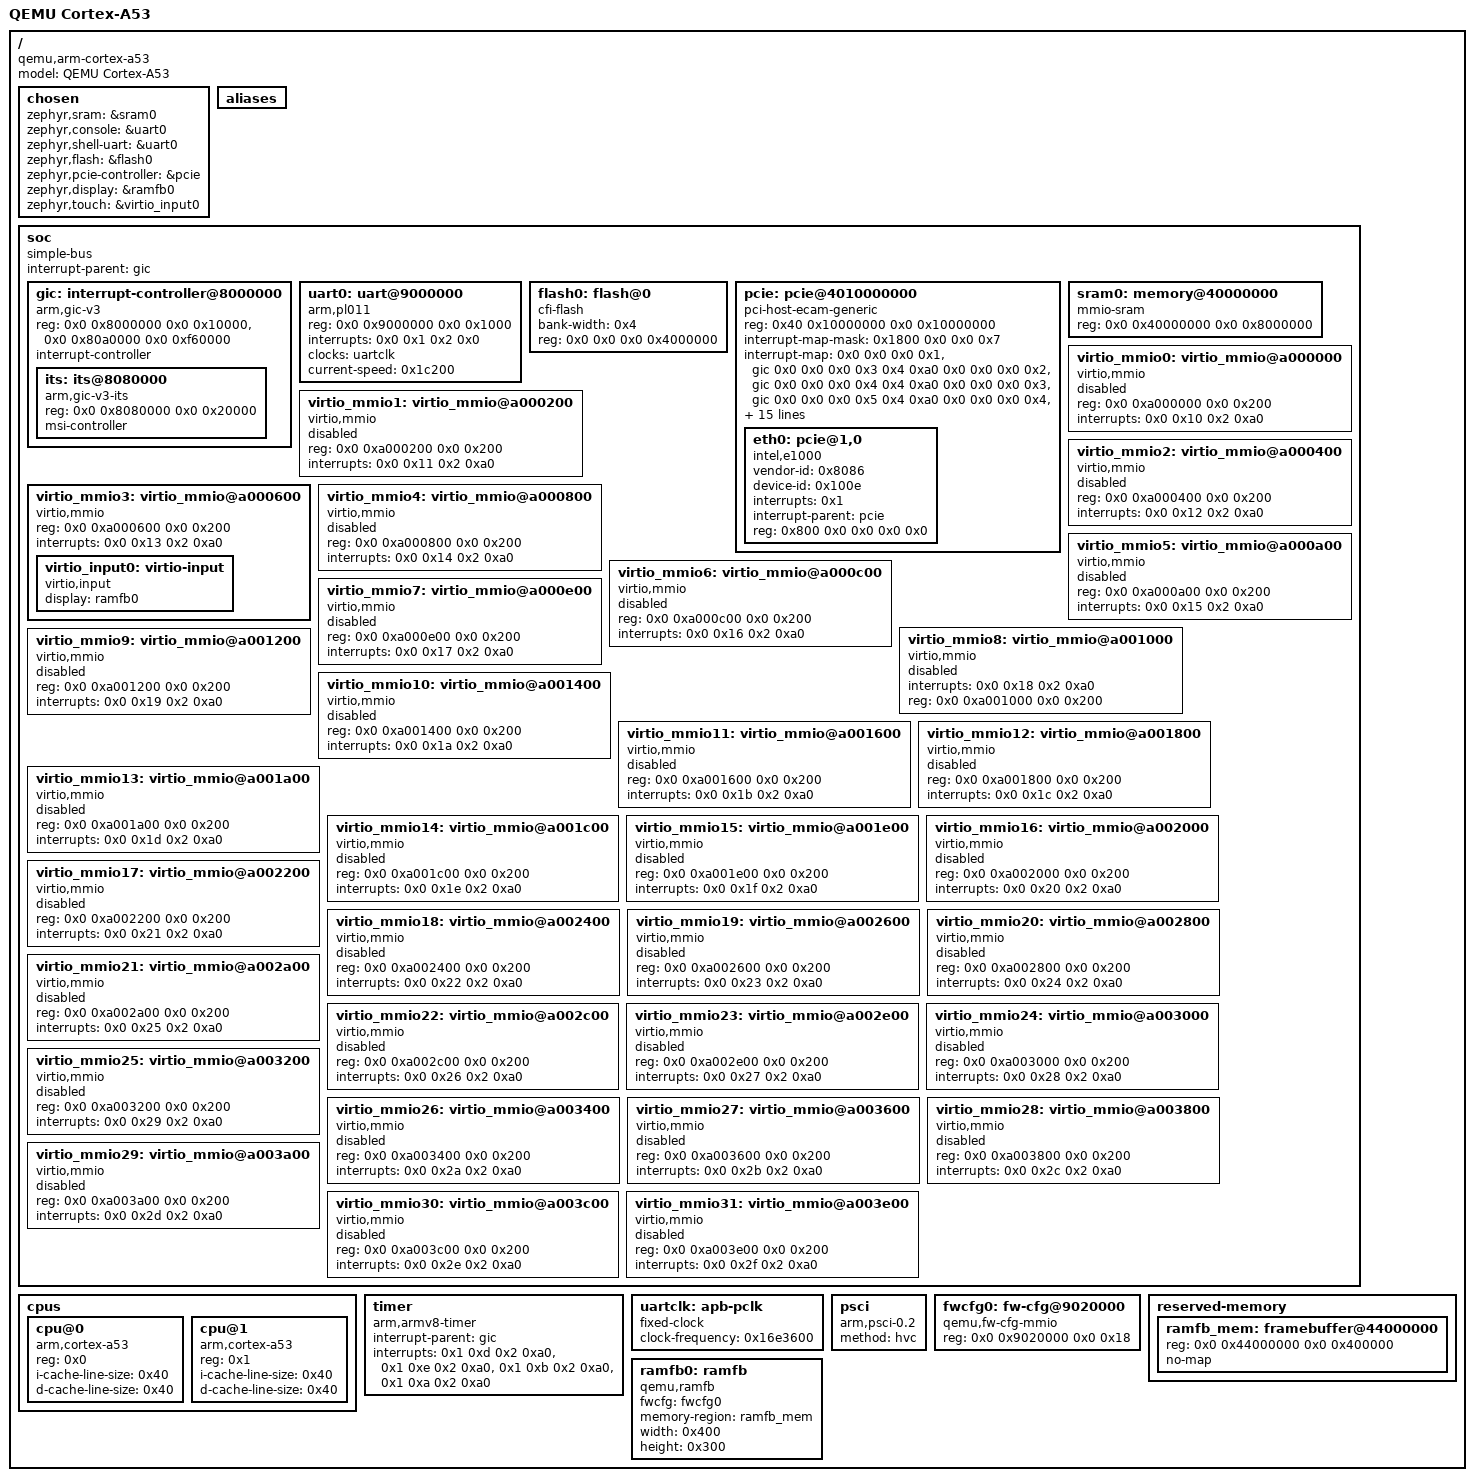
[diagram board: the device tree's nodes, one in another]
/dts-v1/;

/* node '/' defined in zephyr/dts/common/skeleton.dtsi:9 */
/ {
	#address-cells = < 0x2 >;           /* in zephyr/dts/arm64/qemu/qemu-virt-a53.dtsi:22 */
	#size-cells = < 0x2 >;              /* in zephyr/dts/arm64/qemu/qemu-virt-a53.dtsi:23 */
	model = "QEMU Cortex-A53";          /* in zephyr/boards/qemu/cortex_a53/qemu_cortex_a53.dts:12 */
	compatible = "qemu,arm-cortex-a53"; /* in zephyr/boards/qemu/cortex_a53/qemu_cortex_a53.dts:13 */

	/* node '/chosen' defined in zephyr/dts/common/skeleton.dtsi:13 */
	chosen {
		zephyr,sram = &sram0;           /* in zephyr/boards/qemu/cortex_a53/qemu_cortex_a53.dts:21 */
		zephyr,console = &uart0;        /* in zephyr/boards/qemu/cortex_a53/qemu_cortex_a53.dts:22 */
		zephyr,shell-uart = &uart0;     /* in zephyr/boards/qemu/cortex_a53/qemu_cortex_a53.dts:23 */
		zephyr,flash = &flash0;         /* in zephyr/boards/qemu/cortex_a53/qemu_cortex_a53.dts:24 */
		zephyr,pcie-controller = &pcie; /* in zephyr/boards/qemu/cortex_a53/qemu_cortex_a53.dts:25 */
		zephyr,display = &ramfb0;       /* in zephyr/boards/qemu/cortex_a53/qemu_cortex_a53.dts:26 */
		zephyr,touch = &virtio_input0;  /* in zephyr/boards/qemu/cortex_a53/qemu_cortex_a53.dts:27 */
	};

	/* node '/aliases' defined in zephyr/dts/common/skeleton.dtsi:15 */
	aliases {
	};

	/* node '/soc' defined in zephyr/dts/arm64/armv8-a.dtsi:10 */
	soc {
		compatible = "simple-bus";   /* in zephyr/dts/arm64/armv8-a.dtsi:13 */
		#address-cells = < 0x2 >;    /* in zephyr/dts/arm64/qemu/qemu-virt-a53.dtsi:66 */
		#size-cells = < 0x2 >;       /* in zephyr/dts/arm64/qemu/qemu-virt-a53.dtsi:67 */
		ranges;                      /* in zephyr/dts/arm64/qemu/qemu-virt-a53.dtsi:68 */
		interrupt-parent = < &gic >; /* in zephyr/dts/arm64/qemu/qemu-virt-a53.dtsi:70 */

		/* node '/soc/interrupt-controller@8000000' defined in zephyr/dts/arm64/qemu/qemu-virt-a53.dtsi:72 */
		gic: interrupt-controller@8000000 {
			compatible = "arm,gic-v3",
			             "arm,gic";               /* in zephyr/dts/arm64/qemu/qemu-virt-a53.dtsi:73 */
			reg = < 0x0 0x8000000 0x0 0x10000 >,
			      < 0x0 0x80a0000 0x0 0xf60000 >; /* in zephyr/dts/arm64/qemu/qemu-virt-a53.dtsi:74 */
			interrupt-controller;                 /* in zephyr/dts/arm64/qemu/qemu-virt-a53.dtsi:76 */
			#interrupt-cells = < 0x4 >;           /* in zephyr/dts/arm64/qemu/qemu-virt-a53.dtsi:77 */
			status = "okay";                      /* in zephyr/dts/arm64/qemu/qemu-virt-a53.dtsi:78 */
			#size-cells = < 0x2 >;                /* in zephyr/dts/arm64/qemu/qemu-virt-a53.dtsi:79 */
			#address-cells = < 0x2 >;             /* in zephyr/dts/arm64/qemu/qemu-virt-a53.dtsi:80 */
			phandle = < 0x1 >;                    /* in zephyr/dts/arm64/qemu/qemu-virt-a53.dtsi:70 */

			/* node '/soc/interrupt-controller@8000000/its@8080000' defined in zephyr/dts/arm64/qemu/qemu-virt-a53.dtsi:82 */
			its: its@8080000 {
				compatible = "arm,gic-v3-its";       /* in zephyr/dts/arm64/qemu/qemu-virt-a53.dtsi:83 */
				reg = < 0x0 0x8080000 0x0 0x20000 >; /* in zephyr/dts/arm64/qemu/qemu-virt-a53.dtsi:84 */
				msi-controller;                      /* in zephyr/dts/arm64/qemu/qemu-virt-a53.dtsi:85 */
				phandle = < 0x3 >;                   /* in zephyr/dts/arm64/qemu/qemu-virt-a53.dtsi:151 */
			};
		};

		/* node '/soc/uart@9000000' defined in zephyr/dts/arm64/qemu/qemu-virt-a53.dtsi:89 */
		uart0: uart@9000000 {
			compatible = "arm,pl011";           /* in zephyr/dts/arm64/qemu/qemu-virt-a53.dtsi:90 */
			reg = < 0x0 0x9000000 0x0 0x1000 >; /* in zephyr/dts/arm64/qemu/qemu-virt-a53.dtsi:91 */
			interrupts = < 0x0 0x1 0x2 0x0 >;   /* in zephyr/dts/arm64/qemu/qemu-virt-a53.dtsi:93 */
			interrupt-names = "irq_0";          /* in zephyr/dts/arm64/qemu/qemu-virt-a53.dtsi:94 */
			clocks = < &uartclk >;              /* in zephyr/dts/arm64/qemu/qemu-virt-a53.dtsi:95 */
			status = "okay";                    /* in zephyr/boards/qemu/cortex_a53/qemu_cortex_a53.dts:289 */
			current-speed = < 0x1c200 >;        /* in zephyr/boards/qemu/cortex_a53/qemu_cortex_a53.dts:290 */
		};

		/* node '/soc/flash@0' defined in zephyr/dts/arm64/qemu/qemu-virt-a53.dtsi:98 */
		flash0: flash@0 {
			compatible = "cfi-flash";        /* in zephyr/dts/arm64/qemu/qemu-virt-a53.dtsi:99 */
			bank-width = < 0x4 >;            /* in zephyr/dts/arm64/qemu/qemu-virt-a53.dtsi:100 */
			reg = < 0x0 0x0 0x0 0x4000000 >; /* in zephyr/dts/arm64/qemu/qemu-virt-a53.dtsi:105 */
		};

		/* node '/soc/pcie@4010000000' defined in zephyr/dts/arm64/qemu/qemu-virt-a53.dtsi:108 */
		pcie: pcie@4010000000 {
			compatible = "pci-host-ecam-generic";                                                                 /* in zephyr/dts/arm64/qemu/qemu-virt-a53.dtsi:109 */
			device_type = "pci";                                                                                  /* in zephyr/dts/arm64/qemu/qemu-virt-a53.dtsi:110 */
			reg = < 0x40 0x10000000 0x0 0x10000000 >;                                                             /* in zephyr/dts/arm64/qemu/qemu-virt-a53.dtsi:111 */
			#size-cells = < 0x2 >;                                                                                /* in zephyr/dts/arm64/qemu/qemu-virt-a53.dtsi:112 */
			#address-cells = < 0x3 >;                                                                             /* in zephyr/dts/arm64/qemu/qemu-virt-a53.dtsi:113 */
			ranges = < 0x1000000 0x0 0x0 0x0 0x3eff0000 0x0 0x10000 0x2000000 0x0 0x10000000 0x0 0x10000000
			           0x0 0x2eff0000 0x3000000 0x80 0x0 0x80 0x0 0x80 0x0 >;                                     /* in zephyr/dts/arm64/qemu/qemu-virt-a53.dtsi:114 */
			#interrupt-cells = < 0x1 >;                                                                           /* in zephyr/dts/arm64/qemu/qemu-virt-a53.dtsi:117 */
			interrupt-map-mask = < 0x1800 0x0 0x0 0x7 >;                                                          /* in zephyr/dts/arm64/qemu/qemu-virt-a53.dtsi:118 */
			interrupt-map = < 0x0 0x0 0x0 0x1 &gic 0x0 0x0 0x0 0x3 0x4 0xa0 0x0 0x0 0x0 0x2 &gic 0x0 0x0 0x0 0x4
			                  0x4 0xa0 0x0 0x0 0x0 0x3 &gic 0x0 0x0 0x0 0x5 0x4 0xa0 0x0 0x0 0x0 0x4 &gic 0x0 0x0
			                  0x0 0x6 0x4 0xa0 0x800 0x0 0x0 0x1 &gic 0x0 0x0 0x0 0x4 0x4 0xa0 0x800 0x0 0x0 0x2
			                  &gic 0x0 0x0 0x0 0x5 0x4 0xa0 0x800 0x0 0x0 0x3 &gic 0x0 0x0 0x0 0x6 0x4 0xa0 0x800
			                  0x0 0x0 0x4 &gic 0x0 0x0 0x0 0x3 0x4 0xa0 0x1000 0x0 0x0 0x1 &gic 0x0 0x0 0x0 0x5
			                  0x4 0xa0 0x1000 0x0 0x0 0x2 &gic 0x0 0x0 0x0 0x6 0x4 0xa0 0x1000 0x0 0x0 0x3 &gic
			                  0x0 0x0 0x0 0x3 0x4 0xa0 0x1000 0x0 0x0 0x4 &gic 0x0 0x0 0x0 0x4 0x4 0xa0 0x1800
			                  0x0 0x0 0x1 &gic 0x0 0x0 0x0 0x6 0x4 0xa0 0x1800 0x0 0x0 0x2 &gic 0x0 0x0 0x0 0x3
			                  0x4 0xa0 0x1800 0x0 0x0 0x3 &gic 0x0 0x0 0x0 0x4 0x4 0xa0 0x1800 0x0 0x0 0x4 &gic
			                  0x0 0x0 0x0 0x5 0x4 0xa0 >;                                                         /* in zephyr/dts/arm64/qemu/qemu-virt-a53.dtsi:119 */
			msi-parent = < &its >;                                                                                /* in zephyr/dts/arm64/qemu/qemu-virt-a53.dtsi:151 */
			bus-range = < 0x0 0xff >;                                                                             /* in zephyr/dts/arm64/qemu/qemu-virt-a53.dtsi:152 */
			phandle = < 0x4 >;                                                                                    /* in zephyr/boards/qemu/cortex_a53/qemu_cortex_a53.dts:309 */

			/* node '/soc/pcie@4010000000/pcie@1,0' defined in zephyr/boards/qemu/cortex_a53/qemu_cortex_a53.dts:304 */
			eth0: pcie@1,0 {
				compatible = "intel,e1000";      /* in zephyr/boards/qemu/cortex_a53/qemu_cortex_a53.dts:305 */
				vendor-id = < 0x8086 >;          /* in zephyr/boards/qemu/cortex_a53/qemu_cortex_a53.dts:306 */
				device-id = < 0x100e >;          /* in zephyr/boards/qemu/cortex_a53/qemu_cortex_a53.dts:307 */
				interrupts = < 0x1 >;            /* in zephyr/boards/qemu/cortex_a53/qemu_cortex_a53.dts:308 */
				interrupt-parent = < &pcie >;    /* in zephyr/boards/qemu/cortex_a53/qemu_cortex_a53.dts:309 */
				reg = < 0x800 0x0 0x0 0x0 0x0 >; /* in zephyr/boards/qemu/cortex_a53/qemu_cortex_a53.dts:310 */
				status = "okay";                 /* in zephyr/boards/qemu/cortex_a53/qemu_cortex_a53.dts:311 */
			};
		};

		/* node '/soc/memory@40000000' defined in zephyr/boards/qemu/cortex_a53/qemu_cortex_a53.dts:31 */
		sram0: memory@40000000 {
			compatible = "mmio-sram";               /* in zephyr/boards/qemu/cortex_a53/qemu_cortex_a53.dts:32 */
			reg = < 0x0 0x40000000 0x0 0x8000000 >; /* in zephyr/boards/qemu/cortex_a53/qemu_cortex_a53.dts:33 */
		};

		/* node '/soc/virtio_mmio@a000000' defined in zephyr/boards/qemu/cortex_a53/qemu_cortex_a53.dts:36 */
		virtio_mmio0: virtio_mmio@a000000 {
			compatible = "virtio,mmio";         /* in zephyr/boards/qemu/cortex_a53/qemu_cortex_a53.dts:37 */
			reg = < 0x0 0xa000000 0x0 0x200 >;  /* in zephyr/boards/qemu/cortex_a53/qemu_cortex_a53.dts:38 */
			interrupts = < 0x0 0x10 0x2 0xa0 >; /* in zephyr/boards/qemu/cortex_a53/qemu_cortex_a53.dts:39 */
			status = "disabled";                /* in zephyr/boards/qemu/cortex_a53/qemu_cortex_a53.dts:40 */
		};

		/* node '/soc/virtio_mmio@a000200' defined in zephyr/boards/qemu/cortex_a53/qemu_cortex_a53.dts:43 */
		virtio_mmio1: virtio_mmio@a000200 {
			compatible = "virtio,mmio";         /* in zephyr/boards/qemu/cortex_a53/qemu_cortex_a53.dts:44 */
			reg = < 0x0 0xa000200 0x0 0x200 >;  /* in zephyr/boards/qemu/cortex_a53/qemu_cortex_a53.dts:45 */
			interrupts = < 0x0 0x11 0x2 0xa0 >; /* in zephyr/boards/qemu/cortex_a53/qemu_cortex_a53.dts:46 */
			status = "disabled";                /* in zephyr/boards/qemu/cortex_a53/qemu_cortex_a53.dts:47 */
		};

		/* node '/soc/virtio_mmio@a000400' defined in zephyr/boards/qemu/cortex_a53/qemu_cortex_a53.dts:50 */
		virtio_mmio2: virtio_mmio@a000400 {
			compatible = "virtio,mmio";         /* in zephyr/boards/qemu/cortex_a53/qemu_cortex_a53.dts:51 */
			reg = < 0x0 0xa000400 0x0 0x200 >;  /* in zephyr/boards/qemu/cortex_a53/qemu_cortex_a53.dts:52 */
			interrupts = < 0x0 0x12 0x2 0xa0 >; /* in zephyr/boards/qemu/cortex_a53/qemu_cortex_a53.dts:53 */
			status = "disabled";                /* in zephyr/boards/qemu/cortex_a53/qemu_cortex_a53.dts:54 */
		};

		/* node '/soc/virtio_mmio@a000600' defined in zephyr/boards/qemu/cortex_a53/qemu_cortex_a53.dts:57 */
		virtio_mmio3: virtio_mmio@a000600 {
			compatible = "virtio,mmio";         /* in zephyr/boards/qemu/cortex_a53/qemu_cortex_a53.dts:58 */
			reg = < 0x0 0xa000600 0x0 0x200 >;  /* in zephyr/boards/qemu/cortex_a53/qemu_cortex_a53.dts:59 */
			interrupts = < 0x0 0x13 0x2 0xa0 >; /* in zephyr/boards/qemu/cortex_a53/qemu_cortex_a53.dts:60 */
			status = "okay";                    /* in zephyr/boards/qemu/cortex_a53/qemu_cortex_a53.dts:294 */

			/* node '/soc/virtio_mmio@a000600/virtio-input' defined in zephyr/boards/qemu/cortex_a53/qemu_cortex_a53.dts:296 */
			virtio_input0: virtio-input {
				compatible = "virtio,input"; /* in zephyr/boards/qemu/cortex_a53/qemu_cortex_a53.dts:297 */
				display = < &ramfb0 >;       /* in zephyr/boards/qemu/cortex_a53/qemu_cortex_a53.dts:298 */
				status = "okay";             /* in zephyr/boards/qemu/cortex_a53/qemu_cortex_a53.dts:299 */
			};
		};

		/* node '/soc/virtio_mmio@a000800' defined in zephyr/boards/qemu/cortex_a53/qemu_cortex_a53.dts:64 */
		virtio_mmio4: virtio_mmio@a000800 {
			compatible = "virtio,mmio";         /* in zephyr/boards/qemu/cortex_a53/qemu_cortex_a53.dts:65 */
			reg = < 0x0 0xa000800 0x0 0x200 >;  /* in zephyr/boards/qemu/cortex_a53/qemu_cortex_a53.dts:66 */
			interrupts = < 0x0 0x14 0x2 0xa0 >; /* in zephyr/boards/qemu/cortex_a53/qemu_cortex_a53.dts:67 */
			status = "disabled";                /* in zephyr/boards/qemu/cortex_a53/qemu_cortex_a53.dts:68 */
		};

		/* node '/soc/virtio_mmio@a000a00' defined in zephyr/boards/qemu/cortex_a53/qemu_cortex_a53.dts:71 */
		virtio_mmio5: virtio_mmio@a000a00 {
			compatible = "virtio,mmio";         /* in zephyr/boards/qemu/cortex_a53/qemu_cortex_a53.dts:72 */
			reg = < 0x0 0xa000a00 0x0 0x200 >;  /* in zephyr/boards/qemu/cortex_a53/qemu_cortex_a53.dts:73 */
			interrupts = < 0x0 0x15 0x2 0xa0 >; /* in zephyr/boards/qemu/cortex_a53/qemu_cortex_a53.dts:74 */
			status = "disabled";                /* in zephyr/boards/qemu/cortex_a53/qemu_cortex_a53.dts:75 */
		};

		/* node '/soc/virtio_mmio@a000c00' defined in zephyr/boards/qemu/cortex_a53/qemu_cortex_a53.dts:78 */
		virtio_mmio6: virtio_mmio@a000c00 {
			compatible = "virtio,mmio";         /* in zephyr/boards/qemu/cortex_a53/qemu_cortex_a53.dts:79 */
			reg = < 0x0 0xa000c00 0x0 0x200 >;  /* in zephyr/boards/qemu/cortex_a53/qemu_cortex_a53.dts:80 */
			interrupts = < 0x0 0x16 0x2 0xa0 >; /* in zephyr/boards/qemu/cortex_a53/qemu_cortex_a53.dts:81 */
			status = "disabled";                /* in zephyr/boards/qemu/cortex_a53/qemu_cortex_a53.dts:82 */
		};

		/* node '/soc/virtio_mmio@a000e00' defined in zephyr/boards/qemu/cortex_a53/qemu_cortex_a53.dts:85 */
		virtio_mmio7: virtio_mmio@a000e00 {
			compatible = "virtio,mmio";         /* in zephyr/boards/qemu/cortex_a53/qemu_cortex_a53.dts:86 */
			reg = < 0x0 0xa000e00 0x0 0x200 >;  /* in zephyr/boards/qemu/cortex_a53/qemu_cortex_a53.dts:87 */
			interrupts = < 0x0 0x17 0x2 0xa0 >; /* in zephyr/boards/qemu/cortex_a53/qemu_cortex_a53.dts:88 */
			status = "disabled";                /* in zephyr/boards/qemu/cortex_a53/qemu_cortex_a53.dts:89 */
		};

		/* node '/soc/virtio_mmio@a001000' defined in zephyr/boards/qemu/cortex_a53/qemu_cortex_a53.dts:92 */
		virtio_mmio8: virtio_mmio@a001000 {
			compatible = "virtio,mmio";         /* in zephyr/boards/qemu/cortex_a53/qemu_cortex_a53.dts:93 */
			interrupts = < 0x0 0x18 0x2 0xa0 >; /* in zephyr/boards/qemu/cortex_a53/qemu_cortex_a53.dts:94 */
			reg = < 0x0 0xa001000 0x0 0x200 >;  /* in zephyr/boards/qemu/cortex_a53/qemu_cortex_a53.dts:95 */
			status = "disabled";                /* in zephyr/boards/qemu/cortex_a53/qemu_cortex_a53.dts:96 */
		};

		/* node '/soc/virtio_mmio@a001200' defined in zephyr/boards/qemu/cortex_a53/qemu_cortex_a53.dts:99 */
		virtio_mmio9: virtio_mmio@a001200 {
			compatible = "virtio,mmio";         /* in zephyr/boards/qemu/cortex_a53/qemu_cortex_a53.dts:100 */
			reg = < 0x0 0xa001200 0x0 0x200 >;  /* in zephyr/boards/qemu/cortex_a53/qemu_cortex_a53.dts:101 */
			interrupts = < 0x0 0x19 0x2 0xa0 >; /* in zephyr/boards/qemu/cortex_a53/qemu_cortex_a53.dts:102 */
			status = "disabled";                /* in zephyr/boards/qemu/cortex_a53/qemu_cortex_a53.dts:103 */
		};

		/* node '/soc/virtio_mmio@a001400' defined in zephyr/boards/qemu/cortex_a53/qemu_cortex_a53.dts:106 */
		virtio_mmio10: virtio_mmio@a001400 {
			compatible = "virtio,mmio";         /* in zephyr/boards/qemu/cortex_a53/qemu_cortex_a53.dts:107 */
			reg = < 0x0 0xa001400 0x0 0x200 >;  /* in zephyr/boards/qemu/cortex_a53/qemu_cortex_a53.dts:108 */
			interrupts = < 0x0 0x1a 0x2 0xa0 >; /* in zephyr/boards/qemu/cortex_a53/qemu_cortex_a53.dts:109 */
			status = "disabled";                /* in zephyr/boards/qemu/cortex_a53/qemu_cortex_a53.dts:110 */
		};

		/* node '/soc/virtio_mmio@a001600' defined in zephyr/boards/qemu/cortex_a53/qemu_cortex_a53.dts:113 */
		virtio_mmio11: virtio_mmio@a001600 {
			compatible = "virtio,mmio";         /* in zephyr/boards/qemu/cortex_a53/qemu_cortex_a53.dts:114 */
			reg = < 0x0 0xa001600 0x0 0x200 >;  /* in zephyr/boards/qemu/cortex_a53/qemu_cortex_a53.dts:115 */
			interrupts = < 0x0 0x1b 0x2 0xa0 >; /* in zephyr/boards/qemu/cortex_a53/qemu_cortex_a53.dts:116 */
			status = "disabled";                /* in zephyr/boards/qemu/cortex_a53/qemu_cortex_a53.dts:117 */
		};

		/* node '/soc/virtio_mmio@a001800' defined in zephyr/boards/qemu/cortex_a53/qemu_cortex_a53.dts:120 */
		virtio_mmio12: virtio_mmio@a001800 {
			compatible = "virtio,mmio";         /* in zephyr/boards/qemu/cortex_a53/qemu_cortex_a53.dts:121 */
			reg = < 0x0 0xa001800 0x0 0x200 >;  /* in zephyr/boards/qemu/cortex_a53/qemu_cortex_a53.dts:122 */
			interrupts = < 0x0 0x1c 0x2 0xa0 >; /* in zephyr/boards/qemu/cortex_a53/qemu_cortex_a53.dts:123 */
			status = "disabled";                /* in zephyr/boards/qemu/cortex_a53/qemu_cortex_a53.dts:124 */
		};

		/* node '/soc/virtio_mmio@a001a00' defined in zephyr/boards/qemu/cortex_a53/qemu_cortex_a53.dts:127 */
		virtio_mmio13: virtio_mmio@a001a00 {
			compatible = "virtio,mmio";         /* in zephyr/boards/qemu/cortex_a53/qemu_cortex_a53.dts:128 */
			reg = < 0x0 0xa001a00 0x0 0x200 >;  /* in zephyr/boards/qemu/cortex_a53/qemu_cortex_a53.dts:129 */
			interrupts = < 0x0 0x1d 0x2 0xa0 >; /* in zephyr/boards/qemu/cortex_a53/qemu_cortex_a53.dts:130 */
			status = "disabled";                /* in zephyr/boards/qemu/cortex_a53/qemu_cortex_a53.dts:131 */
		};

		/* node '/soc/virtio_mmio@a001c00' defined in zephyr/boards/qemu/cortex_a53/qemu_cortex_a53.dts:134 */
		virtio_mmio14: virtio_mmio@a001c00 {
			compatible = "virtio,mmio";         /* in zephyr/boards/qemu/cortex_a53/qemu_cortex_a53.dts:135 */
			reg = < 0x0 0xa001c00 0x0 0x200 >;  /* in zephyr/boards/qemu/cortex_a53/qemu_cortex_a53.dts:136 */
			interrupts = < 0x0 0x1e 0x2 0xa0 >; /* in zephyr/boards/qemu/cortex_a53/qemu_cortex_a53.dts:137 */
			status = "disabled";                /* in zephyr/boards/qemu/cortex_a53/qemu_cortex_a53.dts:138 */
		};

		/* node '/soc/virtio_mmio@a001e00' defined in zephyr/boards/qemu/cortex_a53/qemu_cortex_a53.dts:141 */
		virtio_mmio15: virtio_mmio@a001e00 {
			compatible = "virtio,mmio";         /* in zephyr/boards/qemu/cortex_a53/qemu_cortex_a53.dts:142 */
			reg = < 0x0 0xa001e00 0x0 0x200 >;  /* in zephyr/boards/qemu/cortex_a53/qemu_cortex_a53.dts:143 */
			interrupts = < 0x0 0x1f 0x2 0xa0 >; /* in zephyr/boards/qemu/cortex_a53/qemu_cortex_a53.dts:144 */
			status = "disabled";                /* in zephyr/boards/qemu/cortex_a53/qemu_cortex_a53.dts:145 */
		};

		/* node '/soc/virtio_mmio@a002000' defined in zephyr/boards/qemu/cortex_a53/qemu_cortex_a53.dts:148 */
		virtio_mmio16: virtio_mmio@a002000 {
			compatible = "virtio,mmio";         /* in zephyr/boards/qemu/cortex_a53/qemu_cortex_a53.dts:149 */
			reg = < 0x0 0xa002000 0x0 0x200 >;  /* in zephyr/boards/qemu/cortex_a53/qemu_cortex_a53.dts:150 */
			interrupts = < 0x0 0x20 0x2 0xa0 >; /* in zephyr/boards/qemu/cortex_a53/qemu_cortex_a53.dts:151 */
			status = "disabled";                /* in zephyr/boards/qemu/cortex_a53/qemu_cortex_a53.dts:152 */
		};

		/* node '/soc/virtio_mmio@a002200' defined in zephyr/boards/qemu/cortex_a53/qemu_cortex_a53.dts:155 */
		virtio_mmio17: virtio_mmio@a002200 {
			compatible = "virtio,mmio";         /* in zephyr/boards/qemu/cortex_a53/qemu_cortex_a53.dts:156 */
			reg = < 0x0 0xa002200 0x0 0x200 >;  /* in zephyr/boards/qemu/cortex_a53/qemu_cortex_a53.dts:157 */
			interrupts = < 0x0 0x21 0x2 0xa0 >; /* in zephyr/boards/qemu/cortex_a53/qemu_cortex_a53.dts:158 */
			status = "disabled";                /* in zephyr/boards/qemu/cortex_a53/qemu_cortex_a53.dts:159 */
		};

		/* node '/soc/virtio_mmio@a002400' defined in zephyr/boards/qemu/cortex_a53/qemu_cortex_a53.dts:162 */
		virtio_mmio18: virtio_mmio@a002400 {
			compatible = "virtio,mmio";         /* in zephyr/boards/qemu/cortex_a53/qemu_cortex_a53.dts:163 */
			reg = < 0x0 0xa002400 0x0 0x200 >;  /* in zephyr/boards/qemu/cortex_a53/qemu_cortex_a53.dts:164 */
			interrupts = < 0x0 0x22 0x2 0xa0 >; /* in zephyr/boards/qemu/cortex_a53/qemu_cortex_a53.dts:165 */
			status = "disabled";                /* in zephyr/boards/qemu/cortex_a53/qemu_cortex_a53.dts:166 */
		};

		/* node '/soc/virtio_mmio@a002600' defined in zephyr/boards/qemu/cortex_a53/qemu_cortex_a53.dts:169 */
		virtio_mmio19: virtio_mmio@a002600 {
			compatible = "virtio,mmio";         /* in zephyr/boards/qemu/cortex_a53/qemu_cortex_a53.dts:170 */
			reg = < 0x0 0xa002600 0x0 0x200 >;  /* in zephyr/boards/qemu/cortex_a53/qemu_cortex_a53.dts:171 */
			interrupts = < 0x0 0x23 0x2 0xa0 >; /* in zephyr/boards/qemu/cortex_a53/qemu_cortex_a53.dts:172 */
			status = "disabled";                /* in zephyr/boards/qemu/cortex_a53/qemu_cortex_a53.dts:173 */
		};

		/* node '/soc/virtio_mmio@a002800' defined in zephyr/boards/qemu/cortex_a53/qemu_cortex_a53.dts:176 */
		virtio_mmio20: virtio_mmio@a002800 {
			compatible = "virtio,mmio";         /* in zephyr/boards/qemu/cortex_a53/qemu_cortex_a53.dts:177 */
			reg = < 0x0 0xa002800 0x0 0x200 >;  /* in zephyr/boards/qemu/cortex_a53/qemu_cortex_a53.dts:178 */
			interrupts = < 0x0 0x24 0x2 0xa0 >; /* in zephyr/boards/qemu/cortex_a53/qemu_cortex_a53.dts:179 */
			status = "disabled";                /* in zephyr/boards/qemu/cortex_a53/qemu_cortex_a53.dts:180 */
		};

		/* node '/soc/virtio_mmio@a002a00' defined in zephyr/boards/qemu/cortex_a53/qemu_cortex_a53.dts:183 */
		virtio_mmio21: virtio_mmio@a002a00 {
			compatible = "virtio,mmio";         /* in zephyr/boards/qemu/cortex_a53/qemu_cortex_a53.dts:184 */
			reg = < 0x0 0xa002a00 0x0 0x200 >;  /* in zephyr/boards/qemu/cortex_a53/qemu_cortex_a53.dts:185 */
			interrupts = < 0x0 0x25 0x2 0xa0 >; /* in zephyr/boards/qemu/cortex_a53/qemu_cortex_a53.dts:186 */
			status = "disabled";                /* in zephyr/boards/qemu/cortex_a53/qemu_cortex_a53.dts:187 */
		};

		/* node '/soc/virtio_mmio@a002c00' defined in zephyr/boards/qemu/cortex_a53/qemu_cortex_a53.dts:190 */
		virtio_mmio22: virtio_mmio@a002c00 {
			compatible = "virtio,mmio";         /* in zephyr/boards/qemu/cortex_a53/qemu_cortex_a53.dts:191 */
			reg = < 0x0 0xa002c00 0x0 0x200 >;  /* in zephyr/boards/qemu/cortex_a53/qemu_cortex_a53.dts:192 */
			interrupts = < 0x0 0x26 0x2 0xa0 >; /* in zephyr/boards/qemu/cortex_a53/qemu_cortex_a53.dts:193 */
			status = "disabled";                /* in zephyr/boards/qemu/cortex_a53/qemu_cortex_a53.dts:194 */
		};

		/* node '/soc/virtio_mmio@a002e00' defined in zephyr/boards/qemu/cortex_a53/qemu_cortex_a53.dts:197 */
		virtio_mmio23: virtio_mmio@a002e00 {
			compatible = "virtio,mmio";         /* in zephyr/boards/qemu/cortex_a53/qemu_cortex_a53.dts:198 */
			reg = < 0x0 0xa002e00 0x0 0x200 >;  /* in zephyr/boards/qemu/cortex_a53/qemu_cortex_a53.dts:199 */
			interrupts = < 0x0 0x27 0x2 0xa0 >; /* in zephyr/boards/qemu/cortex_a53/qemu_cortex_a53.dts:200 */
			status = "disabled";                /* in zephyr/boards/qemu/cortex_a53/qemu_cortex_a53.dts:201 */
		};

		/* node '/soc/virtio_mmio@a003000' defined in zephyr/boards/qemu/cortex_a53/qemu_cortex_a53.dts:204 */
		virtio_mmio24: virtio_mmio@a003000 {
			compatible = "virtio,mmio";         /* in zephyr/boards/qemu/cortex_a53/qemu_cortex_a53.dts:205 */
			reg = < 0x0 0xa003000 0x0 0x200 >;  /* in zephyr/boards/qemu/cortex_a53/qemu_cortex_a53.dts:206 */
			interrupts = < 0x0 0x28 0x2 0xa0 >; /* in zephyr/boards/qemu/cortex_a53/qemu_cortex_a53.dts:207 */
			status = "disabled";                /* in zephyr/boards/qemu/cortex_a53/qemu_cortex_a53.dts:208 */
		};

		/* node '/soc/virtio_mmio@a003200' defined in zephyr/boards/qemu/cortex_a53/qemu_cortex_a53.dts:211 */
		virtio_mmio25: virtio_mmio@a003200 {
			compatible = "virtio,mmio";         /* in zephyr/boards/qemu/cortex_a53/qemu_cortex_a53.dts:212 */
			reg = < 0x0 0xa003200 0x0 0x200 >;  /* in zephyr/boards/qemu/cortex_a53/qemu_cortex_a53.dts:213 */
			interrupts = < 0x0 0x29 0x2 0xa0 >; /* in zephyr/boards/qemu/cortex_a53/qemu_cortex_a53.dts:214 */
			status = "disabled";                /* in zephyr/boards/qemu/cortex_a53/qemu_cortex_a53.dts:215 */
		};

		/* node '/soc/virtio_mmio@a003400' defined in zephyr/boards/qemu/cortex_a53/qemu_cortex_a53.dts:218 */
		virtio_mmio26: virtio_mmio@a003400 {
			compatible = "virtio,mmio";         /* in zephyr/boards/qemu/cortex_a53/qemu_cortex_a53.dts:219 */
			reg = < 0x0 0xa003400 0x0 0x200 >;  /* in zephyr/boards/qemu/cortex_a53/qemu_cortex_a53.dts:220 */
			interrupts = < 0x0 0x2a 0x2 0xa0 >; /* in zephyr/boards/qemu/cortex_a53/qemu_cortex_a53.dts:221 */
			status = "disabled";                /* in zephyr/boards/qemu/cortex_a53/qemu_cortex_a53.dts:222 */
		};

		/* node '/soc/virtio_mmio@a003600' defined in zephyr/boards/qemu/cortex_a53/qemu_cortex_a53.dts:225 */
		virtio_mmio27: virtio_mmio@a003600 {
			compatible = "virtio,mmio";         /* in zephyr/boards/qemu/cortex_a53/qemu_cortex_a53.dts:226 */
			reg = < 0x0 0xa003600 0x0 0x200 >;  /* in zephyr/boards/qemu/cortex_a53/qemu_cortex_a53.dts:227 */
			interrupts = < 0x0 0x2b 0x2 0xa0 >; /* in zephyr/boards/qemu/cortex_a53/qemu_cortex_a53.dts:228 */
			status = "disabled";                /* in zephyr/boards/qemu/cortex_a53/qemu_cortex_a53.dts:229 */
		};

		/* node '/soc/virtio_mmio@a003800' defined in zephyr/boards/qemu/cortex_a53/qemu_cortex_a53.dts:232 */
		virtio_mmio28: virtio_mmio@a003800 {
			compatible = "virtio,mmio";         /* in zephyr/boards/qemu/cortex_a53/qemu_cortex_a53.dts:233 */
			reg = < 0x0 0xa003800 0x0 0x200 >;  /* in zephyr/boards/qemu/cortex_a53/qemu_cortex_a53.dts:234 */
			interrupts = < 0x0 0x2c 0x2 0xa0 >; /* in zephyr/boards/qemu/cortex_a53/qemu_cortex_a53.dts:235 */
			status = "disabled";                /* in zephyr/boards/qemu/cortex_a53/qemu_cortex_a53.dts:236 */
		};

		/* node '/soc/virtio_mmio@a003a00' defined in zephyr/boards/qemu/cortex_a53/qemu_cortex_a53.dts:239 */
		virtio_mmio29: virtio_mmio@a003a00 {
			compatible = "virtio,mmio";         /* in zephyr/boards/qemu/cortex_a53/qemu_cortex_a53.dts:240 */
			reg = < 0x0 0xa003a00 0x0 0x200 >;  /* in zephyr/boards/qemu/cortex_a53/qemu_cortex_a53.dts:241 */
			interrupts = < 0x0 0x2d 0x2 0xa0 >; /* in zephyr/boards/qemu/cortex_a53/qemu_cortex_a53.dts:242 */
			status = "disabled";                /* in zephyr/boards/qemu/cortex_a53/qemu_cortex_a53.dts:243 */
		};

		/* node '/soc/virtio_mmio@a003c00' defined in zephyr/boards/qemu/cortex_a53/qemu_cortex_a53.dts:246 */
		virtio_mmio30: virtio_mmio@a003c00 {
			compatible = "virtio,mmio";         /* in zephyr/boards/qemu/cortex_a53/qemu_cortex_a53.dts:247 */
			reg = < 0x0 0xa003c00 0x0 0x200 >;  /* in zephyr/boards/qemu/cortex_a53/qemu_cortex_a53.dts:248 */
			interrupts = < 0x0 0x2e 0x2 0xa0 >; /* in zephyr/boards/qemu/cortex_a53/qemu_cortex_a53.dts:249 */
			status = "disabled";                /* in zephyr/boards/qemu/cortex_a53/qemu_cortex_a53.dts:250 */
		};

		/* node '/soc/virtio_mmio@a003e00' defined in zephyr/boards/qemu/cortex_a53/qemu_cortex_a53.dts:253 */
		virtio_mmio31: virtio_mmio@a003e00 {
			compatible = "virtio,mmio";         /* in zephyr/boards/qemu/cortex_a53/qemu_cortex_a53.dts:254 */
			reg = < 0x0 0xa003e00 0x0 0x200 >;  /* in zephyr/boards/qemu/cortex_a53/qemu_cortex_a53.dts:255 */
			interrupts = < 0x0 0x2f 0x2 0xa0 >; /* in zephyr/boards/qemu/cortex_a53/qemu_cortex_a53.dts:256 */
			status = "disabled";                /* in zephyr/boards/qemu/cortex_a53/qemu_cortex_a53.dts:257 */
		};
	};

	/* node '/cpus' defined in zephyr/dts/arm64/qemu/qemu-virt-a53.dtsi:25 */
	cpus {
		#address-cells = < 0x1 >; /* in zephyr/dts/arm64/qemu/qemu-virt-a53.dtsi:26 */
		#size-cells = < 0x0 >;    /* in zephyr/dts/arm64/qemu/qemu-virt-a53.dtsi:27 */

		/* node '/cpus/cpu@0' defined in zephyr/dts/arm64/qemu/qemu-virt-a53.dtsi:29 */
		cpu@0 {
			device_type = "cpu";           /* in zephyr/dts/arm64/qemu/qemu-virt-a53.dtsi:30 */
			compatible = "arm,cortex-a53"; /* in zephyr/dts/arm64/qemu/qemu-virt-a53.dtsi:31 */
			reg = < 0x0 >;                 /* in zephyr/dts/arm64/qemu/qemu-virt-a53.dtsi:32 */
			i-cache-line-size = < 0x40 >;  /* in zephyr/dts/arm64/qemu/qemu-virt-a53.dtsi:33 */
			d-cache-line-size = < 0x40 >;  /* in zephyr/dts/arm64/qemu/qemu-virt-a53.dtsi:34 */
		};

		/* node '/cpus/cpu@1' defined in zephyr/dts/arm64/qemu/qemu-virt-a53.dtsi:37 */
		cpu@1 {
			device_type = "cpu";           /* in zephyr/dts/arm64/qemu/qemu-virt-a53.dtsi:38 */
			compatible = "arm,cortex-a53"; /* in zephyr/dts/arm64/qemu/qemu-virt-a53.dtsi:39 */
			reg = < 0x1 >;                 /* in zephyr/dts/arm64/qemu/qemu-virt-a53.dtsi:40 */
			i-cache-line-size = < 0x40 >;  /* in zephyr/dts/arm64/qemu/qemu-virt-a53.dtsi:41 */
			d-cache-line-size = < 0x40 >;  /* in zephyr/dts/arm64/qemu/qemu-virt-a53.dtsi:42 */
		};
	};

	/* node '/timer' defined in zephyr/dts/arm64/qemu/qemu-virt-a53.dtsi:46 */
	timer {
		compatible = "arm,armv8-timer";    /* in zephyr/dts/arm64/qemu/qemu-virt-a53.dtsi:47 */
		interrupt-parent = < &gic >;       /* in zephyr/dts/arm64/qemu/qemu-virt-a53.dtsi:48 */
		interrupts = < 0x1 0xd 0x2 0xa0 >,
		             < 0x1 0xe 0x2 0xa0 >,
		             < 0x1 0xb 0x2 0xa0 >,
		             < 0x1 0xa 0x2 0xa0 >; /* in zephyr/dts/arm64/qemu/qemu-virt-a53.dtsi:49 */
	};

	/* node '/apb-pclk' defined in zephyr/dts/arm64/qemu/qemu-virt-a53.dtsi:59 */
	uartclk: apb-pclk {
		compatible = "fixed-clock";      /* in zephyr/dts/arm64/qemu/qemu-virt-a53.dtsi:60 */
		clock-frequency = < 0x16e3600 >; /* in zephyr/dts/arm64/qemu/qemu-virt-a53.dtsi:61 */
		#clock-cells = < 0x0 >;          /* in zephyr/dts/arm64/qemu/qemu-virt-a53.dtsi:62 */
		phandle = < 0x2 >;               /* in zephyr/dts/arm64/qemu/qemu-virt-a53.dtsi:95 */
	};

	/* node '/psci' defined in zephyr/boards/qemu/cortex_a53/qemu_cortex_a53.dts:15 */
	psci {
		compatible = "arm,psci-0.2"; /* in zephyr/boards/qemu/cortex_a53/qemu_cortex_a53.dts:16 */
		method = "hvc";              /* in zephyr/boards/qemu/cortex_a53/qemu_cortex_a53.dts:17 */
	};

	/* node '/fw-cfg@9020000' defined in zephyr/boards/qemu/cortex_a53/qemu_cortex_a53.dts:261 */
	fwcfg0: fw-cfg@9020000 {
		compatible = "qemu,fw-cfg-mmio";  /* in zephyr/boards/qemu/cortex_a53/qemu_cortex_a53.dts:262 */
		reg = < 0x0 0x9020000 0x0 0x18 >; /* in zephyr/boards/qemu/cortex_a53/qemu_cortex_a53.dts:263 */
		status = "okay";                  /* in zephyr/boards/qemu/cortex_a53/qemu_cortex_a53.dts:264 */
		phandle = < 0x6 >;                /* in zephyr/boards/qemu/cortex_a53/qemu_cortex_a53.dts:280 */
	};

	/* node '/reserved-memory' defined in zephyr/boards/qemu/cortex_a53/qemu_cortex_a53.dts:267 */
	reserved-memory {
		#address-cells = < 0x2 >; /* in zephyr/boards/qemu/cortex_a53/qemu_cortex_a53.dts:268 */
		#size-cells = < 0x2 >;    /* in zephyr/boards/qemu/cortex_a53/qemu_cortex_a53.dts:269 */
		ranges;                   /* in zephyr/boards/qemu/cortex_a53/qemu_cortex_a53.dts:270 */

		/* node '/reserved-memory/framebuffer@44000000' defined in zephyr/boards/qemu/cortex_a53/qemu_cortex_a53.dts:272 */
		ramfb_mem: framebuffer@44000000 {
			reg = < 0x0 0x44000000 0x0 0x400000 >; /* in zephyr/boards/qemu/cortex_a53/qemu_cortex_a53.dts:273 */
			no-map;                                /* in zephyr/boards/qemu/cortex_a53/qemu_cortex_a53.dts:274 */
			phandle = < 0x7 >;                     /* in zephyr/boards/qemu/cortex_a53/qemu_cortex_a53.dts:281 */
		};
	};

	/* node '/ramfb' defined in zephyr/boards/qemu/cortex_a53/qemu_cortex_a53.dts:278 */
	ramfb0: ramfb {
		compatible = "qemu,ramfb";      /* in zephyr/boards/qemu/cortex_a53/qemu_cortex_a53.dts:279 */
		fwcfg = < &fwcfg0 >;            /* in zephyr/boards/qemu/cortex_a53/qemu_cortex_a53.dts:280 */
		memory-region = < &ramfb_mem >; /* in zephyr/boards/qemu/cortex_a53/qemu_cortex_a53.dts:281 */
		width = < 0x400 >;              /* in zephyr/boards/qemu/cortex_a53/qemu_cortex_a53.dts:282 */
		height = < 0x300 >;             /* in zephyr/boards/qemu/cortex_a53/qemu_cortex_a53.dts:283 */
		status = "okay";                /* in zephyr/boards/qemu/cortex_a53/qemu_cortex_a53.dts:284 */
		phandle = < 0x5 >;              /* in zephyr/boards/qemu/cortex_a53/qemu_cortex_a53.dts:298 */
	};
};
